# pocket register map
Vendor: litex
Litex SoC 2023-11-21 06:57:01
Registers are 32-bit, read-write, reset 0x0 unless marked. A register's access mark holds for its fields unless they carry their own. Offsets are from the block's base; lines under a group give offsets from that group; [hi:lo] are bit positions; {n}, {i} and the like mark numbered series; 'fields as' and 'values as' point back to an identical list; <NAME> marks a mode.

## Memory map
0xF0000000 CTRL size 0xC
0xF0000800 IDENTIFIER_MEM size 0x4
0xF0001000 MAIN size 0x80
0xF0001800 SDRAM size 0x34
0xF0002000 TIMER0 size 0x2C
0xF0002800 UART size 0x20
0xF0003000 VIDEO_FRAMEBUFFER size 0x18
0xF0003800 VIDEO_FRAMEBUFFER_VTG size 0x24

## Interrupts
1 uart (UART)
2 timer0 (TIMER0)

## Further device data
memoryRegions:
  PLIC baseAddress=0xF0C00000 size=0x00400000
  CLINT baseAddress=0xF0010000 size=0x00010000
  ROM baseAddress=0x00000000 size=0x00020000
  SRAM baseAddress=0x10000000 size=0x00002000
  MAIN_RAM baseAddress=0x40000000 size=0x04000000
  VIDEO_FRAMEBUFFER baseAddress=0x40C00000 size=0x00800000
  EXAMPLE_SLAVE baseAddress=0x80000000 size=0x00100000
  CSR baseAddress=0xF0000000 size=0x00010000
constants:
  CONFIG_CLOCK_FREQUENCY value=57120000
  CONFIG_CPU_HAS_INTERRUPT value=None
  CONFIG_CPU_RESET_ADDR value=0
  CONFIG_CPU_COUNT value=1
  CONFIG_CPU_ISA value=rv32i2p0_mafdc
  CONFIG_CPU_MMU value=sv32
  CONFIG_CPU_DCACHE_SIZE value=4096
  CONFIG_CPU_DCACHE_WAYS value=1
  CONFIG_CPU_DCACHE_BLOCK_SIZE value=64
  CONFIG_CPU_ICACHE_SIZE value=4096
  CONFIG_CPU_ICACHE_WAYS value=1
  CONFIG_CPU_ICACHE_BLOCK_SIZE value=64
  CONFIG_CPU_DTLB_SIZE value=4
  CONFIG_CPU_DTLB_WAYS value=4
  CONFIG_CPU_ITLB_SIZE value=4
  CONFIG_CPU_ITLB_WAYS value=4
  CONFIG_CPU_TYPE_VEXRISCV_SMP value=None
  CONFIG_CPU_VARIANT_STANDARD value=None
  CONFIG_CPU_HUMAN_NAME value=VexRiscv SMP-STANDARD
  CONFIG_CPU_NOP value=nop
  ROM_BOOT_ADDRESS value=1073741824
  VIDEO_FRAMEBUFFER_BASE value=1086324736
  VIDEO_FRAMEBUFFER_HRES value=266
  VIDEO_FRAMEBUFFER_VRES value=240
  VIDEO_FRAMEBUFFER_DEPTH value=16
  CONFIG_CSR_DATA_WIDTH value=32
  CONFIG_CSR_ALIGNMENT value=32
  CONFIG_BUS_STANDARD value=WISHBONE
  CONFIG_BUS_DATA_WIDTH value=32
  CONFIG_BUS_ADDRESS_WIDTH value=32
  CONFIG_BUS_BURSTING value=0
  CONFIG_CPU_INTERRUPTS value=3
  TIMER0_INTERRUPT value=2
  UART_INTERRUPT value=1

## CTRL
Base 0xF0000000
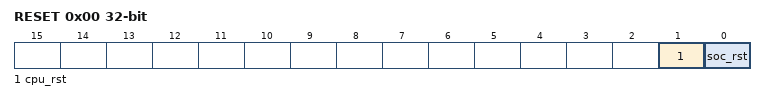
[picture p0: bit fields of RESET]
0x00 RESET
  [1] cpu_rst — Write `1` to this register to reset the CPU(s) of the SoC (Hold Reset)
  [0] soc_rst — Write `1` to this register to reset the full SoC (Pulse Reset)
0x04 SCRATCH reset 0x12345678 — Use this register as a scratch space to verify that software read/write accesses to the Wishbone/CSR bus are working correctly. The initial reset value of 0x1234578 can be used to verify endianness.
0x08 BUS_ERRORS — Total number of Wishbone bus errors (timeouts) since start.

## IDENTIFIER_MEM
Base 0xF0000800
0x00 IDENTIFIER_MEM — 8 x 47-bit memory
  [7:0] identifier_mem

## MAIN
Base 0xF0001000
0x00 CONT1_KEY
0x04 CONT2_KEY
0x08 CONT3_KEY
0x0C CONT4_KEY
{0xC+4i} CONT{i}_JOY (i=1..4)
{0x1C+4i} CONT{i}_TRIG (i=1..4)
0x30 BRIDGE_REQUEST_READ
  [0] bridge_request_read
0x34 BRIDGE_SLOT_ID
  [15:0] bridge_slot_id
0x38 BRIDGE_DATA_OFFSET
0x3C BRIDGE_LENGTH
0x40 RAM_DATA_ADDRESS
0x44 BRIDGE_FILE_SIZE
0x48 BRIDGE_STATUS
  [0] bridge_status
0x4C BRIDGE_CURRENT_ADDRESS
0x50 VSYNC_STATUS
  [0] vsync_status
0x54 VBLANK_STATUS
  [0] vblank_status
0x58 FRAME_COUNTER
0x5C AUDIO_OUT
0x60 AUDIO_PLAYBACK_EN
  [0] audio_playback_en
0x64 AUDIO_BUFFER_FLUSH
  [0] audio_buffer_flush
0x68 AUDIO_BUFFER_FILL
  [11:0] audio_buffer_fill
0x6C RTC_UNIX_SECONDS
0x70 RTC_DATE_BCD
0x74 RTC_TIME_BCD
0x78 CHIP_ID1 — Bits 32-63 of `MAIN_CHIP_ID`.
  [31:0] chip_id
0x7C CHIP_ID0 — Bits 0-31 of `MAIN_CHIP_ID`.
  [31:0] chip_id

## SDRAM
Base 0xF0001800
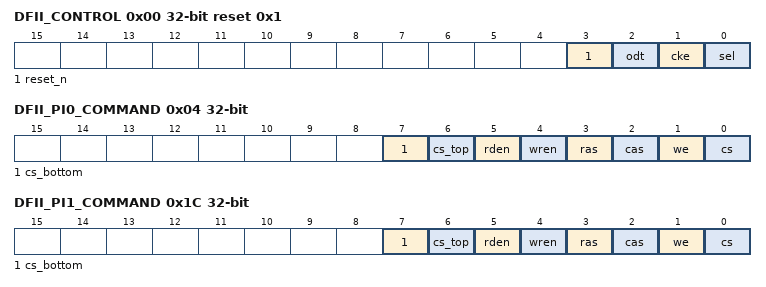
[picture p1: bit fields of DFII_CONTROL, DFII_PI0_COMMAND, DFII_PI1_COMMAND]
0x00 DFII_CONTROL reset 0x1 — Control DFI signals common to all phases
  [3] reset_n — DFI clock reset bus
  [2] odt — DFI on-die termination bus
  [1] cke — DFI clock enable bus
  [0] sel
0x04 DFII_PI0_COMMAND — Control DFI signals on a single phase
  [7] cs_bottom — DFI chip select bus for bottom half only
  [6] cs_top — DFI chip select bus for top half only
  [5] rden — DFI read data enable bus
  [4] wren — DFI write data enable bus
  [3] ras — DFI row address strobe bus
  [2] cas — DFI column address strobe bus
  [1] we — DFI write enable bus
  [0] cs — DFI chip select bus
0x08 DFII_PI0_COMMAND_ISSUE
  [0] dfii_pi0_command_issue
0x0C DFII_PI0_ADDRESS — DFI address bus
  [12:0] dfii_pi0_address
0x10 DFII_PI0_BADDRESS — DFI bank address bus
  [1:0] dfii_pi0_baddress
0x14 DFII_PI0_WRDATA — DFI write data bus
  [15:0] dfii_pi0_wrdata
0x18 DFII_PI0_RDDATA — DFI read data bus
  [15:0] dfii_pi0_rddata
0x1C DFII_PI1_COMMAND — Control DFI signals on a single phase
  fields as DFII_PI0_COMMAND
0x20 DFII_PI1_COMMAND_ISSUE
  [0] dfii_pi1_command_issue
0x24 DFII_PI1_ADDRESS — DFI address bus
  [12:0] dfii_pi1_address
0x28 DFII_PI1_BADDRESS — DFI bank address bus
  [1:0] dfii_pi1_baddress
0x2C DFII_PI1_WRDATA — DFI write data bus
  [15:0] dfii_pi1_wrdata
0x30 DFII_PI1_RDDATA — DFI read data bus
  [15:0] dfii_pi1_rddata

## TIMER0
Base 0xF0002000
0x00 LOAD — Load value when Timer is (re-)enabled. In One-Shot mode, the value written to this register specifies the Timer's duration in clock cycles.
0x04 RELOAD — Reload value when Timer reaches ``0``. In Periodic mode, the value written to this register specify the Timer's period in clock cycles.
0x08 EN — Enable flag of the Timer. Set this flag to ``1`` to enable/start the Timer. Set to ``0`` to disable the Timer.
  [0] en
0x0C UPDATE_VALUE — Update trigger for the current countdown value. A write to this register latches the current countdown value to ``value`` register.
  [0] update_value
0x10 VALUE — Latched countdown value. This value is updated by writing to ``update_value``.
0x14 EV_STATUS — This register contains the current raw level of the zero event trigger. Writes to this register have no effect.
  [0] zero — Level of the ``zero`` event
0x18 EV_PENDING — When a zero event occurs, the corresponding bit will be set in this register. To clear the Event, set the corresponding bit in this register.
  [0] zero — `1` if a `zero` event occurred. This Event is triggered on a **falling** edge.
0x1C EV_ENABLE — This register enables the corresponding zero events. Write a ``0`` to this register to disable individual events.
  [0] zero — Write a ``1`` to enable the ``zero`` Event
0x20 UPTIME_LATCH — Write a ``1`` to latch current Uptime cycles to ``uptime_cycles`` register.
  [0] uptime_latch
0x24 UPTIME_CYCLES1 — Bits 32-63 of `TIMER0_UPTIME_CYCLES`. Latched Uptime since power-up (in ``sys_clk`` cycles).
  [31:0] uptime_cycles
0x28 UPTIME_CYCLES0 — Bits 0-31 of `TIMER0_UPTIME_CYCLES`.
  [31:0] uptime_cycles

## UART
Base 0xF0002800
0x00 RXTX
  [7:0] rxtx
0x04 TXFULL — TX FIFO Full.
  [0] txfull
0x08 RXEMPTY — RX FIFO Empty.
  [0] rxempty
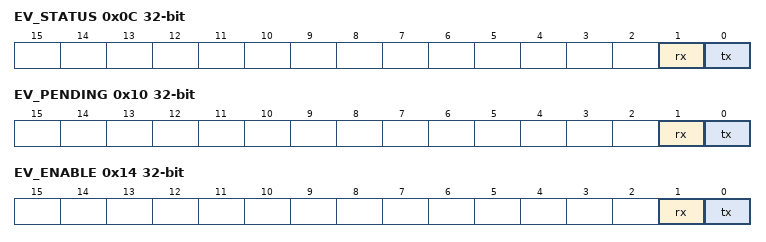
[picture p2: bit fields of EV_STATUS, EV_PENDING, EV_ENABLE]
0x0C EV_STATUS — This register contains the current raw level of the rx event trigger. Writes to this register have no effect.
  [1] rx — Level of the ``rx`` event
  [0] tx — Level of the ``tx`` event
0x10 EV_PENDING — When a rx event occurs, the corresponding bit will be set in this register. To clear the Event, set the corresponding bit in this register.
  [1] rx — `1` if a `rx` event occurred. This Event is triggered on a **falling** edge.
  [0] tx — `1` if a `tx` event occurred. This Event is triggered on a **falling** edge.
0x14 EV_ENABLE — This register enables the corresponding rx events. Write a ``0`` to this register to disable individual events.
  [1] rx — Write a ``1`` to enable the ``rx`` Event
  [0] tx — Write a ``1`` to enable the ``tx`` Event
0x18 TXEMPTY — TX FIFO Empty.
  [0] txempty
0x1C RXFULL — RX FIFO Full.
  [0] rxfull

## VIDEO_FRAMEBUFFER
Base 0xF0003000
0x00 DMA_BASE reset 0x40C00000
0x04 DMA_LENGTH reset 0x1F2C0
0x08 DMA_ENABLE
  [0] dma_enable
0x0C DMA_DONE
  [0] dma_done
0x10 DMA_LOOP reset 0x1
  [0] dma_loop
0x14 DMA_OFFSET

## VIDEO_FRAMEBUFFER_VTG
Base 0xF0003800
0x00 ENABLE reset 0x1
  [0] enable
0x04 HRES reset 0x10A
  [11:0] hres
0x08 HSYNC_START reset 0x112
  [11:0] hsync_start
0x0C HSYNC_END reset 0x132
  [11:0] hsync_end
0x10 HSCAN reset 0x153
  [11:0] hscan
0x14 VRES reset 0xF0
  [11:0] vres
0x18 VSYNC_START reset 0xF1
  [11:0] vsync_start
0x1C VSYNC_END reset 0xF9
  [11:0] vsync_end
0x20 VSCAN reset 0x117
  [11:0] vscan
